# CY8C4245AXI_483 register map
File version: 0.1
PSoC 4200
Registers are 32-bit, read-write, no defined reset value unless marked. A register's access mark holds for its fields unless they carry their own. Offsets are from the block's base; lines under a group give offsets from that group; [hi:lo] are bit positions; {n}, {i} and the like mark numbered series; 'fields as' and 'values as' point back to an identical list; <NAME> marks a mode.

## Memory map
0x00000000 ADC_SAR_Seq_1 — Sequencing SAR ADC
0x00000000 IDAC_Iref — IDAC
0x00000000 UART_BCP — Serial Communication Block
0x00000000 UART_Pi — Serial Communication Block
0x00000000 Counter_Spd
0x00000000 LPComp_OC — Low Power Comparator
0x00000000 CtrlReg_PWMOut
0x00000000 PWM_Drive
0x00000000 Hall_Error
0x00000000 CtrlReg_Dir

## IDAC_Iref — IDAC
Base 0x00000000
0x40080004 CSD_IDAC_POLARITY
0x40080008 CSD_IDAC
0x4008FF00 CSD_TRIM1 — CSD IDAC TRIM1
0x4008FF04 CSD_TRIM2 — CSD IDAC TRIM2

## Counter_Spd
Base 0x00000000
0x40050148 COUNTER — Current counter value
0x4005014C CC — Compare / capture value
0x40050150 CC_BUF — Compare / capture buffer value
0x40050154 PERIOD — Period value
0x40050158 PERIOD_BUF — Period buffer value

## LPComp_OC — Low Power Comparator
Base 0x00000000
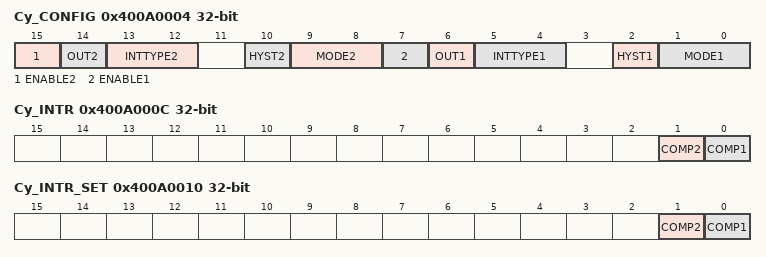
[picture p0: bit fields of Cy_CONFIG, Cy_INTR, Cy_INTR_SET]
0x400A0004 Cy_CONFIG — LPCOMP configuration
  [15] ENABLE2 — Enable comparator #2
    0=DISABLE (Comparator disabled); 1=ENABLE (Comparator enabled)
  [14] OUT2 ro — Current output value of the comparator #2
  [13:12] INTTYPE2 — Sets which edge will trigger an IRQ for the comparator #2
    0=DISABLE (Disabled); 1=RISING (Rising edge); 2=FALLING (Falling edge); 3=BOTH (Both rising and falling edges)
  [10] HYST2 — Selects hysteresis (10mV) for the comparator #2
    0=ENABLE (Hysteresis enabled); 1=DISABLE (Hysteresis disabled)
  [9:8] MODE2 — Selects speed for the comparator #2
    0=MED (Medium speed); 1=FAST (Fast speed); 2=SLOW (Slow speed)
  [7] ENABLE1 — Enable comparator #1
    values as ENABLE2
  [6] OUT1 ro — Current output value of the comparator
  [5:4] INTTYPE1 — Sets which edge will trigger an IRQ for the comparator #1
    values as INTTYPE2
  [2] HYST1 — Selects hysteresis (10mV) for the comparator #1
    values as HYST2
  [1:0] MODE1 — Selects speed for the comparator #1
    values as MODE2
0x400A000C Cy_INTR — LPCOMP interrupt
  [1] COMP2 — Comparator #2 Interrupt: hardware sets this interrupt when comparator 0 triggers. Write with '1' to clear bit.
  [0] COMP1 — Comparator #1 Interrupt: hardware sets this interrupt when comparator 0 triggers. Write with '1' to clear bit.
0x400A0010 Cy_INTR_SET — LPCOMP interrupt set register
  [1] COMP2 — Write with '1' to set corresponding bit in interrupt request register.
  [0] COMP1 — Write with '1' to set corresponding bit in interrupt request register.
0x400AFF00 Cy_TRIM_A — LPCOMP trim A
0x400AFF04 Cy_TRIM_B — LPCOMP trim B

## CtrlReg_PWMOut
Base 0x00000000
0x400F0073 CtrlReg_PWMOut_CONTROL_REG 8-bit

## PWM_Drive
Base 0x00000000
0x40050108 COUNTER — Current counter value
0x4005010C CC — Compare / capture value
0x40050110 CC_BUF — Compare / capture buffer value
0x40050114 PERIOD — Period value
0x40050118 PERIOD_BUF — Period buffer value

## Hall_Error
Base 0x00000000
0x400F0062 Hall_Error_STATUS_REG 8-bit
0x400F0082 Hall_Error_MASK_REG 8-bit
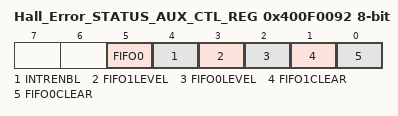
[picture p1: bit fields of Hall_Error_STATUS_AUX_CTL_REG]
0x400F0092 Hall_Error_STATUS_AUX_CTL_REG 8-bit
  [5] FIFO0 — FIFO0 clear
    1=ENABLED (Enable counter); 0=DISABLED (Disable counter)
  [4] INTRENBL — Enables or disables the Interrupt
    1=ENABLED (Interrupt enabled); 0=DISABLED (Interrupt disabled)
  [3] FIFO1LEVEL — FIFO level
    1=ENABLED (FIFO LVL: input mode: FIFO at least 1/2 empty; output mode: FIFO at least 1/2 full); 0=DISABLED (FIFO LVL: input mode: FIFO not full; output mode: FIFO not empty)
  [2] FIFO0LEVEL — FIFO level
    values as FIFO1LEVEL
  [1] FIFO1CLEAR — FIFO clear
    1=ENABLED (Clear FIFO state); 0=DISABLED (Normal FIFO operation)
  [0] FIFO0CLEAR — FIFO clear
    values as FIFO1CLEAR
